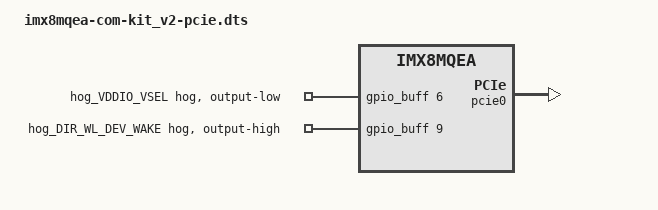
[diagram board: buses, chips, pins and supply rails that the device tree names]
/*
 * Copyright 2019 Embedded Artists AB
 *
 * The code contained herein is licensed under the GNU General Public
 * License. You may obtain a copy of the GNU General Public License
 * Version 2 or later at the following locations:
 *
 * http://www.opensource.org/licenses/gpl-license.html
 * http://www.gnu.org/copyleft/gpl.html
 */

/dts-v1/;
 
#include "imx8mqea-com-kit_v2.dts"


/* TODO: taken from iMX6Q. Valid also for iMX8MQ? */
&gpio_buff {
	hog_VDDIO_VSEL {
		gpio-hog;
		gpios = <6 0>;
		/delete-property/ output-high;
		output-low; /* LOW = 1.8V, HIGH = 3.3V */
	};
	hog_DIR_WL_DEV_WAKE {
		gpio-hog;
		gpios = <9 0>;
		/delete-property/ output-low;
		output-high;
	};
};

&usdhc2_pwrseq {
	status = "disabled";
};

&pcie0 {
	status = "okay";
};

&usdhc2 {
	status = "disabled";
};
